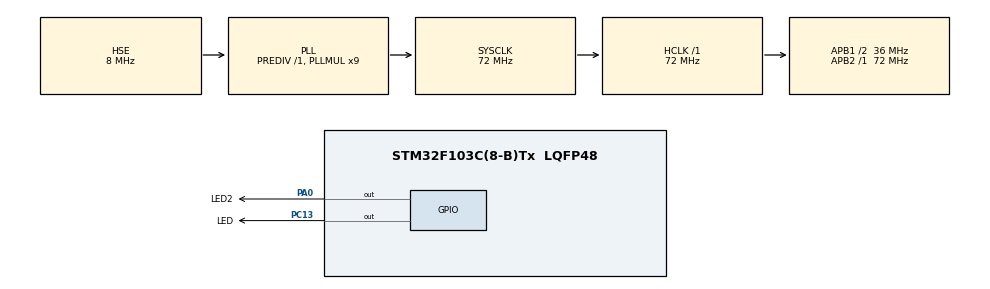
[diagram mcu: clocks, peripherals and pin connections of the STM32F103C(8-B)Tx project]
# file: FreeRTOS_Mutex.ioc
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FREERTOS.Mutexes01=myMutex,Dynamic,NULL,Available
FREERTOS.Tasks01=defaultTask,24,128,StartDefaultTask,Default,NULL,Dynamic,NULL,NULL;Task1,24,128,Task1_start,Default,NULL,Dynamic,NULL,NULL;Task2,24,128,Task2_start,Default,NULL,Dynamic,NULL,NULL
FREERTOS.configUSE_NEWLIB_REENTRANT=1
Mcu.Family=STM32F1
Mcu.Name=STM32F103C(8-B)Tx
Mcu.Package=LQFP48
NVIC.PriorityGroup=NVIC_PRIORITYGROUP_4
NVIC.TIM3_IRQn=true\:15\:0\:false\:false\:true\:false\:false\:true\:true
NVIC.TimeBase=TIM3_IRQn
NVIC.TimeBaseIP=TIM3
PA0-WKUP.GPIO_Label=LED2
PA0-WKUP.Signal=GPIO_Output
PA13.Mode=Serial_Wire
PA13.Signal=SYS_JTMS-SWDIO
PA14.Mode=Serial_Wire
PA14.Signal=SYS_JTCK-SWCLK
PC13-TAMPER-RTC.GPIO_Label=LED
PC13-TAMPER-RTC.PinState=GPIO_PIN_SET
PC13-TAMPER-RTC.Signal=GPIO_Output
PD0-OSC_IN.Mode=HSE-External-Oscillator
PD0-OSC_IN.Signal=RCC_OSC_IN
PD1-OSC_OUT.Mode=HSE-External-Oscillator
PD1-OSC_OUT.Signal=RCC_OSC_OUT
ProjectManager.HeapSize=0x200
ProjectManager.StackSize=0x400
ProjectManager.TargetToolchain=STM32CubeIDE
RCC.AHBFreq_Value=72000000
RCC.APB1CLKDivider=RCC_HCLK_DIV2
RCC.APB1Freq_Value=36000000
RCC.APB1TimFreq_Value=72000000
RCC.APB2Freq_Value=72000000
RCC.APB2TimFreq_Value=72000000
RCC.HCLKFreq_Value=72000000
RCC.PLLMUL=RCC_PLL_MUL9
RCC.PLLSourceVirtual=RCC_PLLSOURCE_HSE
RCC.SYSCLKFreq_VALUE=72000000
RCC.SYSCLKSource=RCC_SYSCLKSOURCE_PLLCLK
RCC.USBFreq_Value=72000000
VP_FREERTOS_VS_CMSIS_V2.Mode=CMSIS_V2
VP_SYS_VS_tim3.Mode=TIM3
board=custom

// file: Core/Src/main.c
/* USER CODE BEGIN Header */
/**
  ******************************************************************************
  * @file           : main.c
  * @brief          : Main program body
  ******************************************************************************
  * @attention
  *
  * Copyright (c) 2026 STMicroelectronics.
  * All rights reserved.
  *
  * This software is licensed under terms that can be found in the LICENSE file
  * in the root directory of this software component.
  * If no LICENSE file comes with this software, it is provided AS-IS.
  *
  ******************************************************************************
  */
/* USER CODE END Header */
#include "main.h"
#include "cmsis_os.h"

/* Definitions for defaultTask */
osThreadId_t defaultTaskHandle;
const osThreadAttr_t defaultTask_attributes = {
  .name = "defaultTask",
  .stack_size = 128 * 4,
  .priority = (osPriority_t) osPriorityNormal,
};
/* Definitions for Task1 */
osThreadId_t Task1Handle;
const osThreadAttr_t Task1_attributes = {
  .name = "Task1",
  .stack_size = 128 * 4,
  .priority = (osPriority_t) osPriorityNormal,
};
/* Definitions for Task2 */
osThreadId_t Task2Handle;
const osThreadAttr_t Task2_attributes = {
  .name = "Task2",
  .stack_size = 128 * 4,
  .priority = (osPriority_t) osPriorityNormal,
};
/* Definitions for myMutex */
osMutexId_t myMutexHandle;
const osMutexAttr_t myMutex_attributes = {
  .name = "myMutex"
};

void SystemClock_Config(void);
static void MX_GPIO_Init(void);
void StartDefaultTask(void *argument);
void Task1_start(void *argument);
void Task2_start(void *argument);

int main(void)
{

  /* MCU Configuration--------------------------------------------------------*/

  /* Reset of all peripherals, Initializes the Flash interface and the Systick. */
  HAL_Init();

  /* Configure the system clock */
  SystemClock_Config();

  /* Initialize all configured peripherals */
  MX_GPIO_Init();

  /* Init scheduler */
  osKernelInitialize();
  /* Create the mutex(es) */
  /* creation of myMutex */
  myMutexHandle = osMutexNew(&myMutex_attributes);

  /* Create the thread(s) */
  /* creation of defaultTask */
  defaultTaskHandle = osThreadNew(StartDefaultTask, NULL, &defaultTask_attributes);

  /* creation of Task1 */
  Task1Handle = osThreadNew(Task1_start, NULL, &Task1_attributes);

  /* creation of Task2 */
  Task2Handle = osThreadNew(Task2_start, NULL, &Task2_attributes);

  /* Start scheduler */
  osKernelStart();

  /* We should never get here as control is now taken by the scheduler */

  /* Infinite loop */
  /* USER CODE BEGIN WHILE */
  while (1)
  {
	//  HAL_GPIO_TogglePin(LED_GPIO_Port, LED_Pin);
		//      HAL_Delay(1000);
    /* USER CODE END WHILE */

  }
}

void SystemClock_Config(void)
{
  RCC_OscInitTypeDef RCC_OscInitStruct = {0};
  RCC_ClkInitTypeDef RCC_ClkInitStruct = {0};

  /** Initializes the RCC Oscillators according to the specified parameters
  * in the RCC_OscInitTypeDef structure.
  */
  RCC_OscInitStruct.OscillatorType = RCC_OSCILLATORTYPE_HSE;
  RCC_OscInitStruct.HSEState = RCC_HSE_ON;
  RCC_OscInitStruct.HSEPredivValue = RCC_HSE_PREDIV_DIV1;
  RCC_OscInitStruct.HSIState = RCC_HSI_ON;
  RCC_OscInitStruct.PLL.PLLState = RCC_PLL_ON;
  RCC_OscInitStruct.PLL.PLLSource = RCC_PLLSOURCE_HSE;
  RCC_OscInitStruct.PLL.PLLMUL = RCC_PLL_MUL9;
  if (HAL_RCC_OscConfig(&RCC_OscInitStruct) != HAL_OK)
  {
    Error_Handler();
  }

  /** Initializes the CPU, AHB and APB buses clocks
  */
  RCC_ClkInitStruct.ClockType = RCC_CLOCKTYPE_HCLK|RCC_CLOCKTYPE_SYSCLK
                              |RCC_CLOCKTYPE_PCLK1|RCC_CLOCKTYPE_PCLK2;
  RCC_ClkInitStruct.SYSCLKSource = RCC_SYSCLKSOURCE_PLLCLK;
  RCC_ClkInitStruct.AHBCLKDivider = RCC_SYSCLK_DIV1;
  RCC_ClkInitStruct.APB1CLKDivider = RCC_HCLK_DIV2;
  RCC_ClkInitStruct.APB2CLKDivider = RCC_HCLK_DIV1;

  if (HAL_RCC_ClockConfig(&RCC_ClkInitStruct, FLASH_LATENCY_2) != HAL_OK)
  {
    Error_Handler();
  }
}

static void MX_GPIO_Init(void)
{
  GPIO_InitTypeDef GPIO_InitStruct = {0};

  /* GPIO Ports Clock Enable */
  __HAL_RCC_GPIOC_CLK_ENABLE();
  __HAL_RCC_GPIOD_CLK_ENABLE();
  __HAL_RCC_GPIOA_CLK_ENABLE();

  /*Configure GPIO pin Output Level */
  HAL_GPIO_WritePin(LED_GPIO_Port, LED_Pin, GPIO_PIN_SET);

  /*Configure GPIO pin Output Level */
  HAL_GPIO_WritePin(LED2_GPIO_Port, LED2_Pin, GPIO_PIN_RESET);

  /*Configure GPIO pin : LED_Pin */
  GPIO_InitStruct.Pin = LED_Pin;
  GPIO_InitStruct.Mode = GPIO_MODE_OUTPUT_PP;
  GPIO_InitStruct.Pull = GPIO_NOPULL;
  GPIO_InitStruct.Speed = GPIO_SPEED_FREQ_LOW;
  HAL_GPIO_Init(LED_GPIO_Port, &GPIO_InitStruct);

  /*Configure GPIO pin : LED2_Pin */
  GPIO_InitStruct.Pin = LED2_Pin;
  GPIO_InitStruct.Mode = GPIO_MODE_OUTPUT_PP;
  GPIO_InitStruct.Pull = GPIO_NOPULL;
  GPIO_InitStruct.Speed = GPIO_SPEED_FREQ_LOW;
  HAL_GPIO_Init(LED2_GPIO_Port, &GPIO_InitStruct);

}

void StartDefaultTask(void *argument)
{
  for(;;)
  {
    osDelay(1);
  }
}

void Task1_start(void *argument)
{
  /* USER CODE BEGIN Task1_start */
	 /* USER CODE BEGIN Task1_start */
	  for(;;)
	  {
		  osDelay(500);
	    osMutexAcquire(myMutexHandle, osWaitForever);

	    for(int i = 0; i < 3; i++)
	    {
	      HAL_GPIO_WritePin(LED_GPIO_Port, LED_Pin, GPIO_PIN_RESET); // ON  ✅
	      osDelay(500);
	      HAL_GPIO_WritePin(LED_GPIO_Port, LED_Pin, GPIO_PIN_SET);   // OFF ✅
	      osDelay(500);
	    }

	    osMutexRelease(myMutexHandle);
	    osDelay(1000);
	  }
  /* USER CODE END Task1_start */
}

void Task2_start(void *argument)
{
  /* USER CODE BEGIN Task2_start */
  /* Infinite loop */
	 for(;;)
	  {
	    osMutexAcquire(myMutexHandle, osWaitForever);

	    for(int i = 0; i < 2; i++)
	    {
	      HAL_GPIO_WritePin(LED2_GPIO_Port, LED2_Pin, GPIO_PIN_SET); // ON  ✅
	      osDelay(500);
	     HAL_GPIO_WritePin(LED2_GPIO_Port, LED2_Pin, GPIO_PIN_RESET);   // OFF ✅
	      osDelay(500);
	    }

	    osMutexRelease(myMutexHandle);
	    osDelay(1000);
	  }
  /* USER CODE END Task2_start */
}

void HAL_TIM_PeriodElapsedCallback(TIM_HandleTypeDef *htim)
{
  if (htim->Instance == TIM3)
  {
    HAL_IncTick();
  }
}

void Error_Handler(void)
{
  __disable_irq();
  while (1)
  {
  }
}
